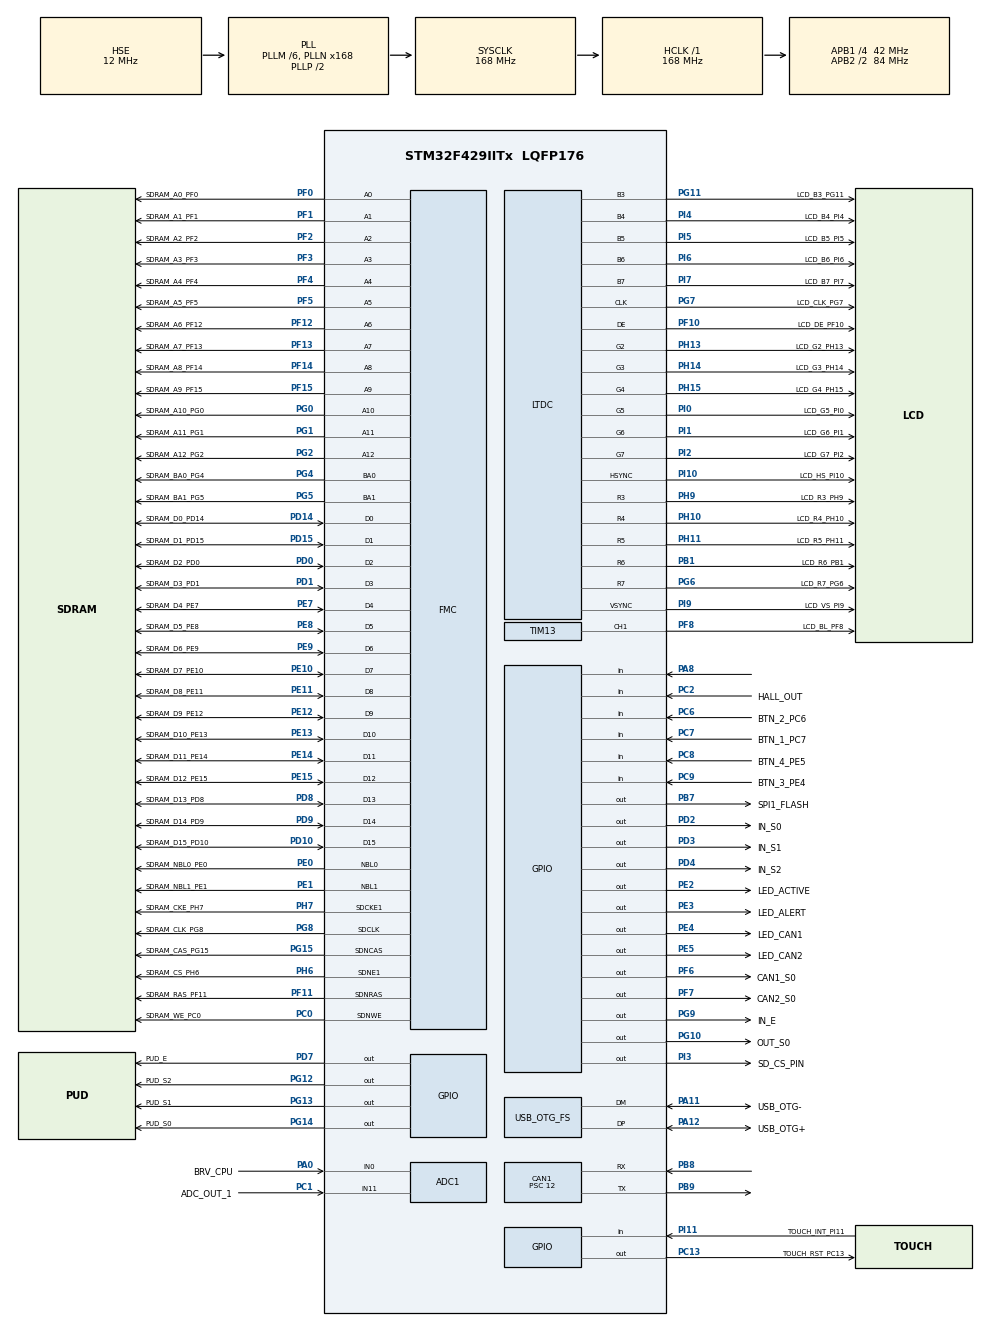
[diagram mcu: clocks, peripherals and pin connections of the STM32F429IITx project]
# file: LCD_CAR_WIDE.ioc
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ADC1.Channel-0\#ChannelRegularConversion=ADC_CHANNEL_11
ADC1.NbrOfConversionFlag=1
ADC1.Rank-0\#ChannelRegularConversion=1
ADC1.SamplingTime-0\#ChannelRegularConversion=ADC_SAMPLETIME_3CYCLES
ADC1.master=1
CAN1.BS1=CAN_BS1_4TQ
CAN1.BS2=CAN_BS2_2TQ
CAN1.CalculateBaudRate=500000
CAN1.CalculateTimeBit=2000
CAN1.CalculateTimeQuantum=285.7142857142857
CAN1.Prescaler=12
DMA2D.ColorMode=DMA2D_OUTPUT_RGB565
DMA2D.InputColorModeBackground=DMA2D_INPUT_RGB565
DMA2D.InputColorModeForeground=DMA2D_INPUT_RGB565
DMA2D.Mode=DMA2D_M2M_BLEND
FMC.CASLatency1=FMC_SDRAM_CAS_LATENCY_3
FMC.ColumnBitsNumber1=FMC_SDRAM_COLUMN_BITS_NUM_9
FMC.ExitSelfRefreshDelay1=8
FMC.LoadToActiveDelay1=2
FMC.RCDDelay1=2
FMC.RPDelay1=2
FMC.ReadBurst1=FMC_SDRAM_RBURST_ENABLE
FMC.ReadPipeDelay1=FMC_SDRAM_RPIPE_DELAY_1
FMC.RowCycleDelay1=7
FMC.SDClockPeriod1=FMC_SDRAM_CLOCK_PERIOD_2
FMC.SelfRefreshTime1=6
FMC.WriteRecoveryTime1=5
FREERTOS.Tasks01=START_Task,24,128,Start_START_Task,Default,NULL,Dynamic,NULL,NULL;TouchGFXTask,40,2048,TouchGFX_Task,As weak,NULL,Dynamic,NULL,NULL;LED_Task,8,128,Start_LED_Task,Default,NULL,Dynamic,NULL,NULL;CAN_Task,8,128,Start_CAN_Task,Default,NULL,Dynamic,NULL,NULL;ALERT_Task,8,128,Start_ALERT_Task,Default,NULL,Dynamic,NULL,NULL;RGB_Task,8,512,Start_RGB_Task,Default,NULL,Dynamic,NULL,NULL
FREERTOS.configASSERT(\ x\ )=if ((x) \=\= 0) {taskDISABLE_INTERRUPTS(); for( ;; );} 
FREERTOS.configMINIMAL_STACK_SIZE=64
FREERTOS.configPRIO_BITS=4
FREERTOS.configTIMER_QUEUE_LENGTH=10
FREERTOS.configTOTAL_HEAP_SIZE=128360
FREERTOS.configUSE_NEWLIB_REENTRANT=1
LTDC.ActiveH=1280
LTDC.ActiveW=480
LTDC.Alpha_L0=255
LTDC.Alpha_L1=255
LTDC.BlendingFactor1_L0=LTDC_BLENDING_FACTOR1_PAxCA
LTDC.BlendingFactor1_L1=LTDC_BLENDING_FACTOR1_PAxCA
LTDC.BlendingFactor2_L0=LTDC_BLENDING_FACTOR2_PAxCA
LTDC.BlendingFactor2_L1=LTDC_BLENDING_FACTOR2_PAxCA
LTDC.Blue_L0=0
LTDC.DEPolarity=LTDC_DEPOLARITY_AL
LTDC.FBStartAdress_L0=0xD0000000
LTDC.FBStartAdress_L1=0xD012C000
LTDC.Green=0
LTDC.Green_L0=0
LTDC.HBP=2
LTDC.HFP=2
LTDC.HSPolarity=LTDC_HSPOLARITY_AL
LTDC.HSync=2
LTDC.ImageHeight_L0=1280
LTDC.ImageHeight_L1=1280
LTDC.ImageWidth_L0=480
LTDC.ImageWidth_L1=480
LTDC.Layers=0
LTDC.PCPolarity=LTDC_PCPOLARITY_IPC
LTDC.PixelFormat_L0=LTDC_PIXEL_FORMAT_RGB565
LTDC.Red=0
LTDC.VBP=40
LTDC.VFP=10
LTDC.VSPolarity=LTDC_VSPOLARITY_AL
LTDC.VSync=20
LTDC.WindowX0_L0=0
LTDC.WindowX1_L0=480
LTDC.WindowX1_L1=480
LTDC.WindowY0_L0=0
LTDC.WindowY1_L0=1280
LTDC.WindowY1_L1=1280
Mcu.Family=STM32F4
Mcu.Name=STM32F429IITx
Mcu.Package=LQFP176
NVIC.CAN1_RX0_IRQn=true\:5\:0\:false\:false\:true\:true\:true\:true\:true
NVIC.DMA2D_IRQn=true\:5\:0\:false\:false\:true\:true\:true\:true\:true
NVIC.FMC_IRQn=true\:5\:0\:false\:false\:true\:true\:true\:true\:true
NVIC.LTDC_IRQn=true\:5\:0\:false\:false\:true\:true\:true\:true\:true
NVIC.OTG_FS_IRQn=true\:5\:0\:false\:false\:true\:true\:false\:true\:true
NVIC.PriorityGroup=NVIC_PRIORITYGROUP_4
NVIC.TIM6_DAC_IRQn=true\:15\:0\:false\:false\:true\:false\:false\:true\:true
NVIC.TimeBase=TIM6_DAC_IRQn
NVIC.TimeBaseIP=TIM6
PA0/WKUP.GPIO_Label=BRV_CPU
PA0/WKUP.Signal=ADCx_IN0
PA11.GPIO_Label=USB_OTG-
PA11.Mode=Device_Only
PA11.Signal=USB_OTG_FS_DM
PA12.GPIO_Label=USB_OTG+
PA12.Mode=Device_Only
PA12.Signal=USB_OTG_FS_DP
PA13.GPIO_Label=SWDIO
PA13.Mode=Serial_Wire
PA13.Signal=SYS_JTMS-SWDIO
PA14.GPIO_Label=SWCLK
PA14.Mode=Serial_Wire
PA14.Signal=SYS_JTCK-SWCLK
PA8.Signal=GPIO_Input
PB1.GPIO_Label=LCD_R6_PB1
PB1.GPIO_Mode=GPIO_MODE_AF_PP
PB1.GPIO_PuPd=GPIO_PULLUP
PB1.GPIO_Speed=GPIO_SPEED_FREQ_VERY_HIGH
PB1.Mode=RGB565
PB1.Signal=LTDC_R6
PB10.GPIO_Label=ESP_TX
PB10.Signal=USART3_TX
PB11.GPIO_Label=ESP_RX
PB11.Signal=USART3_RX
PB12.Signal=CAN2_RX
PB13.Signal=CAN2_TX
PB3.Signal=SPI1_SCK
PB4.Signal=SPI1_MISO
PB5.Signal=SPI1_MOSI
PB7.GPIO_Label=SPI1_FLASH
PB7.Signal=GPIO_Output
PB8.Mode=CAN_Activate
PB8.Signal=CAN1_RX
PB9.Mode=CAN_Activate
PB9.Signal=CAN1_TX
PC0.GPIO_Label=SDRAM_WE_PC0
PC0.Signal=FMC_SDNWE
PC1.GPIO_Label=ADC_OUT_1
PC1.Signal=ADCx_IN11
PC10.Signal=SPI3_SCK
PC11.Signal=SPI3_MISO
PC12.Signal=SPI3_MOSI
PC13.GPIO_Label=TOUCH_RST_PC13
PC13.Signal=GPIO_Output
PC2.GPIO_Label=HALL_OUT
PC2.Signal=GPIO_Input
PC6.GPIO_Label=BTN_2_PC6
PC6.Signal=GPIO_Input
PC7.GPIO_Label=BTN_1_PC7
PC7.Signal=GPIO_Input
PC8.GPIO_Label=BTN_4_PE5
PC8.Signal=GPIO_Input
PC9.GPIO_Label=BTN_3_PE4
PC9.Signal=GPIO_Input
PD0.GPIO_Label=SDRAM_D2_PD0
PD0.Signal=FMC_D2_DA2
PD1.GPIO_Label=SDRAM_D3_PD1
PD1.Signal=FMC_D3_DA3
PD10.GPIO_Label=SDRAM_D15_PD10
PD10.Signal=FMC_D15_DA15
PD14.GPIO_Label=SDRAM_D0_PD14
PD14.Signal=FMC_D0_DA0
PD15.GPIO_Label=SDRAM_D1_PD15
PD15.Signal=FMC_D1_DA1
PD2.GPIO_Label=IN_S0
PD2.Signal=GPIO_Output
PD3.GPIO_Label=IN_S1
PD3.Signal=GPIO_Output
PD4.GPIO_Label=IN_S2
PD4.Signal=GPIO_Output
PD6.GPIO_Label=LCD_B2_PD6
PD6.Signal=LTDC_B2
PD7.GPIO_Label=PUD_E
PD7.Signal=GPIO_Output
PD8.GPIO_Label=SDRAM_D13_PD8
PD8.Signal=FMC_D13_DA13
PD9.GPIO_Label=SDRAM_D14_PD9
PD9.Signal=FMC_D14_DA14
PE0.GPIO_Label=SDRAM_NBL0_PE0
PE0.Signal=FMC_NBL0
PE1.GPIO_Label=SDRAM_NBL1_PE1
PE1.Signal=FMC_NBL1
PE10.GPIO_Label=SDRAM_D7_PE10
PE10.Signal=FMC_D7_DA7
PE11.GPIO_Label=SDRAM_D8_PE11
PE11.Signal=FMC_D8_DA8
PE12.GPIO_Label=SDRAM_D9_PE12
PE12.Signal=FMC_D9_DA9
PE13.GPIO_Label=SDRAM_D10_PE13
PE13.Signal=FMC_D10_DA10
PE14.GPIO_Label=SDRAM_D11_PE14
PE14.Signal=FMC_D11_DA11
PE15.GPIO_Label=SDRAM_D12_PE15
PE15.Signal=FMC_D12_DA12
PE2.GPIO_Label=LED_ACTIVE
PE2.Signal=GPIO_Output
PE3.GPIO_Label=LED_ALERT
PE3.Signal=GPIO_Output
PE4.GPIO_Label=LED_CAN1
PE4.Signal=GPIO_Output
PE5.GPIO_Label=LED_CAN2
PE5.Signal=GPIO_Output
PE7.GPIO_Label=SDRAM_D4_PE7
PE7.Signal=FMC_D4_DA4
PE8.GPIO_Label=SDRAM_D5_PE8
PE8.Signal=FMC_D5_DA5
PE9.GPIO_Label=SDRAM_D6_PE9
PE9.Signal=FMC_D6_DA6
PF0.GPIO_Label=SDRAM_A0_PF0
PF0.Signal=FMC_A0
PF1.GPIO_Label=SDRAM_A1_PF1
PF1.Signal=FMC_A1
PF10.GPIO_Label=LCD_DE_PF10
PF10.GPIO_Mode=GPIO_MODE_AF_PP
PF10.GPIO_PuPd=GPIO_PULLUP
PF10.GPIO_Speed=GPIO_SPEED_FREQ_VERY_HIGH
PF10.Mode=RGB565
PF10.Signal=LTDC_DE
PF11.GPIO_Label=SDRAM_RAS_PF11
PF11.Signal=FMC_SDNRAS
PF12.GPIO_Label=SDRAM_A6_PF12
PF12.Signal=FMC_A6
PF13.GPIO_Label=SDRAM_A7_PF13
PF13.Signal=FMC_A7
PF14.GPIO_Label=SDRAM_A8_PF14
PF14.Signal=FMC_A8
PF15.GPIO_Label=SDRAM_A9_PF15
PF15.Signal=FMC_A9
PF2.GPIO_Label=SDRAM_A2_PF2
PF2.Signal=FMC_A2
PF3.GPIO_Label=SDRAM_A3_PF3
PF3.Signal=FMC_A3
PF4.GPIO_Label=SDRAM_A4_PF4
PF4.Signal=FMC_A4
PF5.GPIO_Label=SDRAM_A5_PF5
PF5.Signal=FMC_A5
PF6.GPIO_Label=CAN1_S0
PF6.GPIO_ModeDefaultOutputPP=GPIO_MODE_OUTPUT_PP
PF6.GPIO_PuPd=GPIO_PULLUP
PF6.PinState=GPIO_PIN_RESET
PF6.Signal=GPIO_Output
PF7.GPIO_Label=CAN2_S0
PF7.GPIO_ModeDefaultOutputPP=GPIO_MODE_OUTPUT_PP
PF7.GPIO_PuPd=GPIO_PULLUP
PF7.PinState=GPIO_PIN_RESET
PF7.Signal=GPIO_Output
PF8.GPIO_Label=LCD_BL_PF8
PF8.Signal=S_TIM13_CH1
PG0.GPIO_Label=SDRAM_A10_PG0
PG0.Signal=FMC_A10
PG1.GPIO_Label=SDRAM_A11_PG1
PG1.Signal=FMC_A11
PG10.GPIO_Label=OUT_S0
PG10.Signal=GPIO_Output
PG11.GPIO_Label=LCD_B3_PG11
PG11.GPIO_Mode=GPIO_MODE_AF_PP
PG11.GPIO_PuPd=GPIO_PULLUP
PG11.GPIO_Speed=GPIO_SPEED_FREQ_VERY_HIGH
PG11.Mode=RGB565
PG11.Signal=LTDC_B3
PG12.GPIO_Label=PUD_S2
PG12.Signal=GPIO_Output
PG13.GPIO_Label=PUD_S1
PG13.Signal=GPIO_Output
PG14.GPIO_Label=PUD_S0
PG14.Signal=GPIO_Output
PG15.GPIO_Label=SDRAM_CAS_PG15
PG15.Signal=FMC_SDNCAS
PG2.GPIO_Label=SDRAM_A12_PG2
PG2.Signal=FMC_A12
PG4.GPIO_Label=SDRAM_BA0_PG4
PG4.Signal=FMC_A14_BA0
PG5.GPIO_Label=SDRAM_BA1_PG5
PG5.Signal=FMC_A15_BA1
PG6.GPIO_Label=LCD_R7_PG6
PG6.GPIO_Mode=GPIO_MODE_AF_PP
PG6.GPIO_PuPd=GPIO_PULLUP
PG6.GPIO_Speed=GPIO_SPEED_FREQ_VERY_HIGH
PG6.Mode=RGB565
PG6.Signal=LTDC_R7
PG7.GPIO_Label=LCD_CLK_PG7
PG7.GPIO_Mode=GPIO_MODE_AF_PP
PG7.GPIO_PuPd=GPIO_PULLUP
PG7.GPIO_Speed=GPIO_SPEED_FREQ_VERY_HIGH
PG7.Mode=RGB565
PG7.Signal=LTDC_CLK
PG8.GPIO_Label=SDRAM_CLK_PG8
PG8.Signal=FMC_SDCLK
PG9.GPIO_Label=IN_E
PG9.Signal=GPIO_Output
PH0/OSC_IN.GPIO_Label=OSC_IN
PH0/OSC_IN.Mode=HSE-External-Oscillator
PH0/OSC_IN.Signal=RCC_OSC_IN
PH1/OSC_OUT.GPIO_Label=OSC_OUT
PH1/OSC_OUT.Mode=HSE-External-Oscillator
PH1/OSC_OUT.Signal=RCC_OSC_OUT
PH10.GPIO_Label=LCD_R4_PH10
PH10.GPIO_Mode=GPIO_MODE_AF_PP
PH10.GPIO_PuPd=GPIO_PULLUP
PH10.GPIO_Speed=GPIO_SPEED_FREQ_VERY_HIGH
PH10.Mode=RGB565
PH10.Signal=LTDC_R4
PH11.GPIO_Label=LCD_R5_PH11
PH11.GPIO_Mode=GPIO_MODE_AF_PP
PH11.GPIO_PuPd=GPIO_PULLUP
PH11.GPIO_Speed=GPIO_SPEED_FREQ_VERY_HIGH
PH11.Mode=RGB565
PH11.Signal=LTDC_R5
PH13.GPIO_Label=LCD_G2_PH13
PH13.GPIO_Mode=GPIO_MODE_AF_PP
PH13.GPIO_PuPd=GPIO_PULLUP
PH13.GPIO_Speed=GPIO_SPEED_FREQ_VERY_HIGH
PH13.Mode=RGB565
PH13.Signal=LTDC_G2
PH14.GPIO_Label=LCD_G3_PH14
PH14.GPIO_Mode=GPIO_MODE_AF_PP
PH14.GPIO_PuPd=GPIO_PULLUP
PH14.GPIO_Speed=GPIO_SPEED_FREQ_VERY_HIGH
PH14.Mode=RGB565
PH14.Signal=LTDC_G3
PH15.GPIO_Label=LCD_G4_PH15
PH15.GPIO_Mode=GPIO_MODE_AF_PP
PH15.GPIO_PuPd=GPIO_PULLUP
PH15.GPIO_Speed=GPIO_SPEED_FREQ_VERY_HIGH
PH15.Mode=RGB565
PH15.Signal=LTDC_G4
PH4.GPIO_Label=I2C2_SCL_PH4
PH4.Signal=I2C2_SCL
PH5.GPIO_Label=I2C2_SDA_PH5
PH5.Signal=I2C2_SDA
PH6.GPIO_Label=SDRAM_CS_PH6
PH6.Mode=SdramChipSelect2_1
PH6.Signal=FMC_SDNE1
PH7.GPIO_Label=SDRAM_CKE_PH7
PH7.Mode=SdramChipSelect2_1
PH7.Signal=FMC_SDCKE1
PH8.GPIO_Label=LCD_R2_PH8
PH8.Signal=LTDC_R2
PH9.GPIO_Label=LCD_R3_PH9
PH9.GPIO_Mode=GPIO_MODE_AF_PP
PH9.GPIO_PuPd=GPIO_PULLUP
PH9.GPIO_Speed=GPIO_SPEED_FREQ_VERY_HIGH
PH9.Mode=RGB565
PH9.Signal=LTDC_R3
PI0.GPIO_Label=LCD_G5_PI0
PI0.GPIO_Mode=GPIO_MODE_AF_PP
PI0.GPIO_PuPd=GPIO_PULLUP
PI0.GPIO_Speed=GPIO_SPEED_FREQ_VERY_HIGH
PI0.Mode=RGB565
PI0.Signal=LTDC_G5
PI1.GPIO_Label=LCD_G6_PI1
PI1.GPIO_Mode=GPIO_MODE_AF_PP
PI1.GPIO_PuPd=GPIO_PULLUP
PI1.GPIO_Speed=GPIO_SPEED_FREQ_VERY_HIGH
PI1.Mode=RGB565
PI1.Signal=LTDC_G6
PI10.GPIO_Label=LCD_HS_PI10
PI10.GPIO_Mode=GPIO_MODE_AF_PP
PI10.GPIO_PuPd=GPIO_PULLUP
PI10.GPIO_Speed=GPIO_SPEED_FREQ_VERY_HIGH
PI10.Mode=RGB565
PI10.Signal=LTDC_HSYNC
PI11.GPIO_Label=TOUCH_INT_PI11
PI11.Signal=GPIO_Input
PI2.GPIO_Label=LCD_G7_PI2
PI2.GPIO_Mode=GPIO_MODE_AF_PP
PI2.GPIO_PuPd=GPIO_PULLUP
PI2.GPIO_Speed=GPIO_SPEED_FREQ_VERY_HIGH
PI2.Mode=RGB565
PI2.Signal=LTDC_G7
PI3.GPIO_Label=SD_CS_PIN
PI3.Signal=GPIO_Output
PI4.GPIO_Label=LCD_B4_PI4
PI4.GPIO_Mode=GPIO_MODE_AF_PP
PI4.GPIO_PuPd=GPIO_PULLUP
PI4.GPIO_Speed=GPIO_SPEED_FREQ_VERY_HIGH
PI4.Mode=RGB565
PI4.Signal=LTDC_B4
PI5.GPIO_Label=LCD_B5_PI5
PI5.GPIO_Mode=GPIO_MODE_AF_PP
PI5.GPIO_PuPd=GPIO_PULLUP
PI5.GPIO_Speed=GPIO_SPEED_FREQ_VERY_HIGH
PI5.Mode=RGB565
PI5.Signal=LTDC_B5
PI6.GPIO_Label=LCD_B6_PI6
PI6.GPIO_Mode=GPIO_MODE_AF_PP
PI6.GPIO_PuPd=GPIO_PULLUP
PI6.GPIO_Speed=GPIO_SPEED_FREQ_VERY_HIGH
PI6.Mode=RGB565
PI6.Signal=LTDC_B6
PI7.GPIO_Label=LCD_B7_PI7
PI7.GPIO_Mode=GPIO_MODE_AF_PP
PI7.GPIO_PuPd=GPIO_PULLUP
PI7.GPIO_Speed=GPIO_SPEED_FREQ_VERY_HIGH
PI7.Mode=RGB565
PI7.Signal=LTDC_B7
PI9.GPIO_Label=LCD_VS_PI9
PI9.GPIO_Mode=GPIO_MODE_AF_PP
PI9.GPIO_PuPd=GPIO_PULLUP
PI9.GPIO_Speed=GPIO_SPEED_FREQ_VERY_HIGH
PI9.Mode=RGB565
PI9.Signal=LTDC_VSYNC
ProjectManager.HeapSize=0x400
ProjectManager.StackSize=0x800
ProjectManager.TargetToolchain=STM32CubeIDE
RCC.48MHZClocksFreq_Value=48000000
RCC.AHBFreq_Value=168000000
RCC.APB1CLKDivider=RCC_HCLK_DIV4
RCC.APB1Freq_Value=42000000
RCC.APB1TimFreq_Value=84000000
RCC.APB2CLKDivider=RCC_HCLK_DIV2
RCC.APB2Freq_Value=84000000
RCC.APB2TimFreq_Value=168000000
RCC.CortexFreq_Value=168000000
RCC.EXTERNAL_CLOCK_VALUE=12288000
RCC.EnbaleCSS=true
RCC.FLatency-AdvancedSettings=FLASH_LATENCY_5
RCC.HCLKFreq_Value=168000000
RCC.HSEUsed=1
RCC.HSE_VALUE=12000000
RCC.HSI_VALUE=16000000
RCC.I2SClockSource=I2S_CLOCK_PLL
RCC.LSEUsed=0
RCC.LSE_VALUE=32768
RCC.LSIUsed=0
RCC.PLLM=6
RCC.PLLN=168
RCC.PLLQ=7
RCC.PLLSAIN=50
RCC.PLLUsed=1
RCC.SAIClockSource_BlockA=SAI_CLKSOURCE_PLLSAI
RCC.SAIClockSource_BlockB=SAI_CLKSOURCE_PLLSAI
RCC.SYSCLKFreq_VALUE=168000000
RCC.SYSCLKSource=RCC_SYSCLKSOURCE_PLLCLK
RCC.VCOOutputFreq_Value=336000000
SH.ADCx_IN0.0=ADC1_IN0,IN0
SH.ADCx_IN11.0=ADC1_IN11,IN11
SH.FMC_A0.0=FMC_A0,13b-sda1
SH.FMC_A1.0=FMC_A1,13b-sda1
SH.FMC_A10.0=FMC_A10,13b-sda1
SH.FMC_A11.0=FMC_A11,13b-sda1
SH.FMC_A12.0=FMC_A12,13b-sda1
SH.FMC_A14_BA0.0=FMC_BA0,FourSdramBanks1
SH.FMC_A15_BA1.0=FMC_BA1,FourSdramBanks1
SH.FMC_A2.0=FMC_A2,13b-sda1
SH.FMC_A3.0=FMC_A3,13b-sda1
SH.FMC_A4.0=FMC_A4,13b-sda1
SH.FMC_A5.0=FMC_A5,13b-sda1
SH.FMC_A6.0=FMC_A6,13b-sda1
SH.FMC_A7.0=FMC_A7,13b-sda1
SH.FMC_A8.0=FMC_A8,13b-sda1
SH.FMC_A9.0=FMC_A9,13b-sda1
SH.FMC_D0_DA0.0=FMC_D0,sd-16b-d1
SH.FMC_D10_DA10.0=FMC_D10,sd-16b-d1
SH.FMC_D11_DA11.0=FMC_D11,sd-16b-d1
SH.FMC_D12_DA12.0=FMC_D12,sd-16b-d1
SH.FMC_D13_DA13.0=FMC_D13,sd-16b-d1
SH.FMC_D14_DA14.0=FMC_D14,sd-16b-d1
SH.FMC_D15_DA15.0=FMC_D15,sd-16b-d1
SH.FMC_D1_DA1.0=FMC_D1,sd-16b-d1
SH.FMC_D2_DA2.0=FMC_D2,sd-16b-d1
SH.FMC_D3_DA3.0=FMC_D3,sd-16b-d1
SH.FMC_D4_DA4.0=FMC_D4,sd-16b-d1
SH.FMC_D5_DA5.0=FMC_D5,sd-16b-d1
SH.FMC_D6_DA6.0=FMC_D6,sd-16b-d1
SH.FMC_D7_DA7.0=FMC_D7,sd-16b-d1
SH.FMC_D8_DA8.0=FMC_D8,sd-16b-d1
SH.FMC_D9_DA9.0=FMC_D9,sd-16b-d1
SH.FMC_NBL0.0=FMC_NBL0,Sd2ByteEnable1
SH.FMC_NBL1.0=FMC_NBL1,Sd2ByteEnable1
SH.FMC_SDCLK.0=FMC_SDCLK,13b-sda1
SH.FMC_SDNCAS.0=FMC_SDNCAS,13b-sda1
SH.FMC_SDNRAS.0=FMC_SDNRAS,13b-sda1
SH.FMC_SDNWE.0=FMC_SDNWE,13b-sda1
SH.S_TIM13_CH1.0=TIM13_CH1,PWM Generation1 CH1
STMicroelectronics.X-CUBE-TOUCHGFX.4.21.1.ApplicationCcGraphicsJjApplication=TouchGFXOoGenerator
STMicroelectronics.X-CUBE-TOUCHGFX.4.21.1.tgfx_address1=0xD0000000
STMicroelectronics.X-CUBE-TOUCHGFX.4.21.1.tgfx_address2=0xD012C000
STMicroelectronics.X-CUBE-TOUCHGFX.4.21.1.tgfx_buffering_strategy=Double
STMicroelectronics.X-CUBE-TOUCHGFX.4.21.1.tgfx_display_interface=disp_ltdc
STMicroelectronics.X-CUBE-TOUCHGFX.4.21.1.tgfx_hardware_accelerator=dma_2d
STMicroelectronics.X-CUBE-TOUCHGFX.4.21.1.tgfx_location=By Address
STMicroelectronics.X-CUBE-TOUCHGFX.4.21.1.tgfx_vsync=vsync_ltdc
STMicroelectronics.X-CUBE-TOUCHGFX.4.21.1_IsPackSelfContextualization=true
TIM1.AutoReloadPreload=TIM_AUTORELOAD_PRELOAD_DISABLE
TIM1.Period=210
TIM13.AutoReloadPreload=TIM_AUTORELOAD_PRELOAD_ENABLE
TIM13.Channel=TIM_CHANNEL_1
TIM13.Period=1000-1
TIM13.Prescaler=90-1
USB_DEVICE.CLASS_NAME_FS=CDC
USB_DEVICE.PID_CDC_FS=57701
USB_DEVICE.PRODUCT_STRING_CDC_FS=OPF Dash
USB_DEVICE.VirtualMode-CDC_FS=Cdc
USB_DEVICE.VirtualModeFS=Cdc_FS
USB_OTG_FS.VirtualMode=Device_Only
VP_CRC_VS_CRC.Mode=CRC_Activate
VP_DMA2D_VS_DMA2D.Mode=DMA2D_Activate
VP_FREERTOS_VS_CMSIS_V2.Mode=CMSIS_V2
VP_STMicroelectronics.X-CUBE-TOUCHGFX_VS_GraphicsJjApplication_4.21.1.Mode=GraphicsJjApplication
VP_SYS_VS_tim6.Mode=TIM6
VP_TIM13_VS_ClockSourceINT.Mode=Enable_Timer
VP_TIM1_VS_ClockSourceINT.Mode=Internal
VP_USB_DEVICE_VS_USB_DEVICE_CDC_FS.Mode=CDC_FS
board=custom

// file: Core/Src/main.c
/* USER CODE BEGIN Header */
/**
 ******************************************************************************
 * @file           : main.c
 * @brief          : Main program body
 ******************************************************************************
 * @attention
 *
 * <h2><center>&copy; Copyright (c) 2021 STMicroelectronics.
 * All rights reserved.</center></h2>
 *
 * This software component is licensed by ST under BSD 3-Clause license,
 * the "License"; You may not use this file except in compliance with the
 * License. You may obtain a copy of the License at:
 *                        opensource.org/licenses/BSD-3-Clause
 *
 ******************************************************************************
 */
/* USER CODE END Header */
#include "main.h"
#include "cmsis_os.h"
#include "app_touchgfx.h"
#include "usb_device.h"

/* USER CODE BEGIN Includes */
//#include <File_Handling.h>
#include <stdio.h>
#include "Globals.h"
#include "extern.h"
#include "sdram.h"
#include "WS2812/WS2812.hpp"

//Setup
#include "Setup/Dash/setupDash.h"
#include "Setup/Field/setupField.h"

/* USER CODE END Includes */

/* USER CODE BEGIN PM */
//#define LCD_ORIENTATION_LANDSCAPE 0x01

/* USER CODE END PM */

ADC_HandleTypeDef hadc1;

CAN_HandleTypeDef hcan1;

CRC_HandleTypeDef hcrc;

DMA2D_HandleTypeDef hdma2d;

LTDC_HandleTypeDef hltdc;

TIM_HandleTypeDef htim1;
TIM_HandleTypeDef htim13;

SDRAM_HandleTypeDef hsdram1;

/* Definitions for START_Task */
osThreadId_t START_TaskHandle;
const osThreadAttr_t START_Task_attributes = {
  .name = "START_Task",
  .stack_size = 128 * 4,
  .priority = (osPriority_t) osPriorityNormal,
};
/* Definitions for TouchGFXTask */
osThreadId_t TouchGFXTaskHandle;
const osThreadAttr_t TouchGFXTask_attributes = {
  .name = "TouchGFXTask",
  .stack_size = 2048 * 4,
  .priority = (osPriority_t) osPriorityHigh,
};
/* Definitions for LED_Task */
osThreadId_t LED_TaskHandle;
const osThreadAttr_t LED_Task_attributes = {
  .name = "LED_Task",
  .stack_size = 128 * 4,
  .priority = (osPriority_t) osPriorityLow,
};
/* Definitions for CAN_Task */
osThreadId_t CAN_TaskHandle;
const osThreadAttr_t CAN_Task_attributes = {
  .name = "CAN_Task",
  .stack_size = 128 * 4,
  .priority = (osPriority_t) osPriorityLow,
};
/* Definitions for ALERT_Task */
osThreadId_t ALERT_TaskHandle;
const osThreadAttr_t ALERT_Task_attributes = {
  .name = "ALERT_Task",
  .stack_size = 128 * 4,
  .priority = (osPriority_t) osPriorityLow,
};
/* Definitions for RGB_Task */
osThreadId_t RGB_TaskHandle;
const osThreadAttr_t RGB_Task_attributes = {
  .name = "RGB_Task",
  .stack_size = 512 * 4,
  .priority = (osPriority_t) osPriorityLow,
};
/* USER CODE BEGIN PV */
FMC_SDRAM_CommandTypeDef command;

Statuses Current_Status;

CAN_TxHeaderTypeDef TxHeader;
CAN_RxHeaderTypeDef RxHeader;
uint8_t TxData[8];
uint8_t RxData[8];

uint8_t uartTransmitBufferSize;
uint8_t uartTransmitBuffer[128];

/* USER CODE END PV */

void SystemClock_Config(void);
static void MX_GPIO_Init(void);
static void MX_LTDC_Init(void);
static void MX_DMA2D_Init(void);
static void MX_FMC_Init(void);
static void MX_CRC_Init(void);
static void MX_TIM13_Init(void);
static void MX_CAN1_Init(void);
static void MX_ADC1_Init(void);
static void MX_TIM1_Init(void);
void Start_START_Task(void *argument);
void TouchGFX_Task(void *argument);
void Start_LED_Task(void *argument);
void Start_CAN_Task(void *argument);
void Start_ALERT_Task(void *argument);
void Start_RGB_Task(void *argument);

int main(void)
{

  /* MCU Configuration--------------------------------------------------------*/

  /* Reset of all peripherals, Initializes the Flash interface and the Systick. */
  HAL_Init();

  /* Configure the system clock */
  SystemClock_Config();

  /* Initialize all configured peripherals */
  MX_GPIO_Init();
  MX_LTDC_Init();
  MX_DMA2D_Init();
  MX_FMC_Init();
  MX_CRC_Init();
  MX_TIM13_Init();
  MX_CAN1_Init();
  MX_ADC1_Init();
  MX_TIM1_Init();
  MX_TouchGFX_Init();
  /* Call PreOsInit function */
  MX_TouchGFX_PreOSInit();
  /* USER CODE BEGIN 2 */

  HAL_TIM_PWM_Start(&htim13, TIM_CHANNEL_1);
  initWS2812();

  /* USER CODE END 2 */

  /* Init scheduler */
  osKernelInitialize();

  /* Create the thread(s) */
  /* creation of START_Task */
  START_TaskHandle = osThreadNew(Start_START_Task, NULL, &START_Task_attributes);

  /* creation of TouchGFXTask */
  TouchGFXTaskHandle = osThreadNew(TouchGFX_Task, NULL, &TouchGFXTask_attributes);

  /* creation of LED_Task */
  LED_TaskHandle = osThreadNew(Start_LED_Task, NULL, &LED_Task_attributes);

  /* creation of CAN_Task */
  CAN_TaskHandle = osThreadNew(Start_CAN_Task, NULL, &CAN_Task_attributes);

  /* creation of ALERT_Task */
  ALERT_TaskHandle = osThreadNew(Start_ALERT_Task, NULL, &ALERT_Task_attributes);

  /* creation of RGB_Task */
  RGB_TaskHandle = osThreadNew(Start_RGB_Task, NULL, &RGB_Task_attributes);

  /* Start scheduler */
  osKernelStart();

  /* We should never get here as control is now taken by the scheduler */
  /* Infinite loop */
	while (1) {

	}
}

void SystemClock_Config(void)
{
  RCC_OscInitTypeDef RCC_OscInitStruct = {0};
  RCC_ClkInitTypeDef RCC_ClkInitStruct = {0};

  /** Configure the main internal regulator output voltage
  */
  __HAL_RCC_PWR_CLK_ENABLE();
  __HAL_PWR_VOLTAGESCALING_CONFIG(PWR_REGULATOR_VOLTAGE_SCALE1);

  /** Initializes the RCC Oscillators according to the specified parameters
  * in the RCC_OscInitTypeDef structure.
  */
  RCC_OscInitStruct.OscillatorType = RCC_OSCILLATORTYPE_HSE;
  RCC_OscInitStruct.HSEState = RCC_HSE_ON;
  RCC_OscInitStruct.PLL.PLLState = RCC_PLL_ON;
  RCC_OscInitStruct.PLL.PLLSource = RCC_PLLSOURCE_HSE;
  RCC_OscInitStruct.PLL.PLLM = 6;
  RCC_OscInitStruct.PLL.PLLN = 168;
  RCC_OscInitStruct.PLL.PLLP = RCC_PLLP_DIV2;
  RCC_OscInitStruct.PLL.PLLQ = 7;
  if (HAL_RCC_OscConfig(&RCC_OscInitStruct) != HAL_OK)
  {
    Error_Handler();
  }

  /** Initializes the CPU, AHB and APB buses clocks
  */
  RCC_ClkInitStruct.ClockType = RCC_CLOCKTYPE_HCLK|RCC_CLOCKTYPE_SYSCLK
                              |RCC_CLOCKTYPE_PCLK1|RCC_CLOCKTYPE_PCLK2;
  RCC_ClkInitStruct.SYSCLKSource = RCC_SYSCLKSOURCE_PLLCLK;
  RCC_ClkInitStruct.AHBCLKDivider = RCC_SYSCLK_DIV1;
  RCC_ClkInitStruct.APB1CLKDivider = RCC_HCLK_DIV4;
  RCC_ClkInitStruct.APB2CLKDivider = RCC_HCLK_DIV2;

  if (HAL_RCC_ClockConfig(&RCC_ClkInitStruct, FLASH_LATENCY_5) != HAL_OK)
  {
    Error_Handler();
  }

  /** Enables the Clock Security System
  */
  HAL_RCC_EnableCSS();
}

static void MX_ADC1_Init(void)
{

  ADC_ChannelConfTypeDef sConfig = {0};

  /** Configure the global features of the ADC (Clock, Resolution, Data Alignment and number of conversion)
  */
  hadc1.Instance = ADC1;
  hadc1.Init.ClockPrescaler = ADC_CLOCK_SYNC_PCLK_DIV4;
  hadc1.Init.Resolution = ADC_RESOLUTION_12B;
  hadc1.Init.ScanConvMode = DISABLE;
  hadc1.Init.ContinuousConvMode = DISABLE;
  hadc1.Init.DiscontinuousConvMode = DISABLE;
  hadc1.Init.ExternalTrigConvEdge = ADC_EXTERNALTRIGCONVEDGE_NONE;
  hadc1.Init.ExternalTrigConv = ADC_SOFTWARE_START;
  hadc1.Init.DataAlign = ADC_DATAALIGN_RIGHT;
  hadc1.Init.NbrOfConversion = 1;
  hadc1.Init.DMAContinuousRequests = DISABLE;
  hadc1.Init.EOCSelection = ADC_EOC_SINGLE_CONV;
  if (HAL_ADC_Init(&hadc1) != HAL_OK)
  {
    Error_Handler();
  }

  /** Configure for the selected ADC regular channel its corresponding rank in the sequencer and its sample time.
  */
  sConfig.Channel = ADC_CHANNEL_11;
  sConfig.Rank = 1;
  sConfig.SamplingTime = ADC_SAMPLETIME_3CYCLES;
  if (HAL_ADC_ConfigChannel(&hadc1, &sConfig) != HAL_OK)
  {
    Error_Handler();
  }

}

static void MX_CAN1_Init(void)
{

  /* USER CODE BEGIN CAN1_Init 0 */

	CAN_FilterTypeDef sFilterConfig; //declare CAN filter structure
  /* USER CODE END CAN1_Init 0 */

  hcan1.Instance = CAN1;
  hcan1.Init.Prescaler = 12;
  hcan1.Init.Mode = CAN_MODE_NORMAL;
  hcan1.Init.SyncJumpWidth = CAN_SJW_1TQ;
  hcan1.Init.TimeSeg1 = CAN_BS1_4TQ;
  hcan1.Init.TimeSeg2 = CAN_BS2_2TQ;
  hcan1.Init.TimeTriggeredMode = DISABLE;
  hcan1.Init.AutoBusOff = DISABLE;
  hcan1.Init.AutoWakeUp = DISABLE;
  hcan1.Init.AutoRetransmission = DISABLE;
  hcan1.Init.ReceiveFifoLocked = DISABLE;
  hcan1.Init.TransmitFifoPriority = DISABLE;
  if (HAL_CAN_Init(&hcan1) != HAL_OK)
  {
    Error_Handler();
  }
  /* USER CODE BEGIN CAN1_Init 2 */
	sFilterConfig.FilterBank = 15;
	sFilterConfig.FilterMode = CAN_FILTERMODE_IDMASK;
	sFilterConfig.FilterScale = CAN_FILTERSCALE_32BIT;
	sFilterConfig.FilterIdHigh = 0x0000;
	sFilterConfig.FilterIdLow = 0x0000;
	sFilterConfig.FilterMaskIdHigh = 0x0000;
	sFilterConfig.FilterMaskIdLow = 0x0000;
	sFilterConfig.FilterFIFOAssignment = CAN_RX_FIFO0;
	sFilterConfig.FilterActivation = ENABLE;
	//sFilterConfig.SlaveStartFilterBank = 14;
	if (HAL_CAN_ConfigFilter(&hcan1, &sFilterConfig) != HAL_OK) {
		/* Filter configuration Error */
		Error_Handler();
	}
	if (HAL_CAN_Start(&hcan1) != HAL_OK) {
		/* Start Error */
		Error_Handler();
	}

	__HAL_RCC_CAN1_CLK_ENABLE();
	//__HAL_RCC_CAN2_CLK_ENABLE();
  /* USER CODE END CAN1_Init 2 */

}

static void MX_CRC_Init(void)
{

  hcrc.Instance = CRC;
  if (HAL_CRC_Init(&hcrc) != HAL_OK)
  {
    Error_Handler();
  }

}

static void MX_DMA2D_Init(void)
{

  hdma2d.Instance = DMA2D;
  hdma2d.Init.Mode = DMA2D_M2M_BLEND;
  hdma2d.Init.ColorMode = DMA2D_OUTPUT_RGB565;
  hdma2d.Init.OutputOffset = 0;
  hdma2d.LayerCfg[0].InputOffset = 0;
  hdma2d.LayerCfg[0].InputColorMode = DMA2D_INPUT_RGB565;
  hdma2d.LayerCfg[0].AlphaMode = DMA2D_NO_MODIF_ALPHA;
  hdma2d.LayerCfg[0].InputAlpha = 0;
  hdma2d.LayerCfg[1].InputOffset = 0;
  hdma2d.LayerCfg[1].InputColorMode = DMA2D_INPUT_RGB565;
  hdma2d.LayerCfg[1].AlphaMode = DMA2D_NO_MODIF_ALPHA;
  hdma2d.LayerCfg[1].InputAlpha = 0;
  if (HAL_DMA2D_Init(&hdma2d) != HAL_OK)
  {
    Error_Handler();
  }
  if (HAL_DMA2D_ConfigLayer(&hdma2d, 0) != HAL_OK)
  {
    Error_Handler();
  }
  if (HAL_DMA2D_ConfigLayer(&hdma2d, 1) != HAL_OK)
  {
    Error_Handler();
  }

}

static void MX_LTDC_Init(void)
{

  LTDC_LayerCfgTypeDef pLayerCfg = {0};

  hltdc.Instance = LTDC;
  hltdc.Init.HSPolarity = LTDC_HSPOLARITY_AL;
  hltdc.Init.VSPolarity = LTDC_VSPOLARITY_AL;
  hltdc.Init.DEPolarity = LTDC_DEPOLARITY_AL;
  hltdc.Init.PCPolarity = LTDC_PCPOLARITY_IPC;
  hltdc.Init.HorizontalSync = 1;
  hltdc.Init.VerticalSync = 19;
  hltdc.Init.AccumulatedHBP = 3;
  hltdc.Init.AccumulatedVBP = 59;
  hltdc.Init.AccumulatedActiveW = 483;
  hltdc.Init.AccumulatedActiveH = 1339;
  hltdc.Init.TotalWidth = 485;
  hltdc.Init.TotalHeigh = 1349;
  hltdc.Init.Backcolor.Blue = 0;
  hltdc.Init.Backcolor.Green = 0;
  hltdc.Init.Backcolor.Red = 0;
  if (HAL_LTDC_Init(&hltdc) != HAL_OK)
  {
    Error_Handler();
  }
  pLayerCfg.WindowX0 = 0;
  pLayerCfg.WindowX1 = 480;
  pLayerCfg.WindowY0 = 0;
  pLayerCfg.WindowY1 = 1280;
  pLayerCfg.PixelFormat = LTDC_PIXEL_FORMAT_RGB565;
  pLayerCfg.Alpha = 255;
  pLayerCfg.Alpha0 = 0;
  pLayerCfg.BlendingFactor1 = LTDC_BLENDING_FACTOR1_PAxCA;
  pLayerCfg.BlendingFactor2 = LTDC_BLENDING_FACTOR2_PAxCA;
  pLayerCfg.FBStartAdress = 0xD0000000;
  pLayerCfg.ImageWidth = 480;
  pLayerCfg.ImageHeight = 1280;
  pLayerCfg.Backcolor.Blue = 0;
  pLayerCfg.Backcolor.Green = 0;
  pLayerCfg.Backcolor.Red = 0;
  if (HAL_LTDC_ConfigLayer(&hltdc, &pLayerCfg, 0) != HAL_OK)
  {
    Error_Handler();
  }

}

static void MX_TIM1_Init(void)
{

  TIM_ClockConfigTypeDef sClockSourceConfig = {0};
  TIM_MasterConfigTypeDef sMasterConfig = {0};

  htim1.Instance = TIM1;
  htim1.Init.Prescaler = 0;
  htim1.Init.CounterMode = TIM_COUNTERMODE_UP;
  htim1.Init.Period = 210;
  htim1.Init.ClockDivision = TIM_CLOCKDIVISION_DIV1;
  htim1.Init.RepetitionCounter = 0;
  htim1.Init.AutoReloadPreload = TIM_AUTORELOAD_PRELOAD_DISABLE;
  if (HAL_TIM_Base_Init(&htim1) != HAL_OK)
  {
    Error_Handler();
  }
  sClockSourceConfig.ClockSource = TIM_CLOCKSOURCE_INTERNAL;
  if (HAL_TIM_ConfigClockSource(&htim1, &sClockSourceConfig) != HAL_OK)
  {
    Error_Handler();
  }
  sMasterConfig.MasterOutputTrigger = TIM_TRGO_RESET;
  sMasterConfig.MasterSlaveMode = TIM_MASTERSLAVEMODE_DISABLE;
  if (HAL_TIMEx_MasterConfigSynchronization(&htim1, &sMasterConfig) != HAL_OK)
  {
    Error_Handler();
  }

}

static void MX_TIM13_Init(void)
{

  TIM_OC_InitTypeDef sConfigOC = {0};

  htim13.Instance = TIM13;
  htim13.Init.Prescaler = 90-1;
  htim13.Init.CounterMode = TIM_COUNTERMODE_UP;
  htim13.Init.Period = 1000-1;
  htim13.Init.ClockDivision = TIM_CLOCKDIVISION_DIV1;
  htim13.Init.AutoReloadPreload = TIM_AUTORELOAD_PRELOAD_ENABLE;
  if (HAL_TIM_Base_Init(&htim13) != HAL_OK)
  {
    Error_Handler();
  }
  if (HAL_TIM_PWM_Init(&htim13) != HAL_OK)
  {
    Error_Handler();
  }
  sConfigOC.OCMode = TIM_OCMODE_PWM1;
  sConfigOC.Pulse = 0;
  sConfigOC.OCPolarity = TIM_OCPOLARITY_HIGH;
  sConfigOC.OCFastMode = TIM_OCFAST_DISABLE;
  if (HAL_TIM_PWM_ConfigChannel(&htim13, &sConfigOC, TIM_CHANNEL_1) != HAL_OK)
  {
    Error_Handler();
  }
  HAL_TIM_MspPostInit(&htim13);

}

/* FMC initialization function */
static void MX_FMC_Init(void)
{

  FMC_SDRAM_TimingTypeDef SdramTiming = {0};

  /** Perform the SDRAM1 memory initialization sequence
  */
  hsdram1.Instance = FMC_SDRAM_DEVICE;
  /* hsdram1.Init */
  hsdram1.Init.SDBank = FMC_SDRAM_BANK2;
  hsdram1.Init.ColumnBitsNumber = FMC_SDRAM_COLUMN_BITS_NUM_9;
  hsdram1.Init.RowBitsNumber = FMC_SDRAM_ROW_BITS_NUM_13;
  hsdram1.Init.MemoryDataWidth = FMC_SDRAM_MEM_BUS_WIDTH_16;
  hsdram1.Init.InternalBankNumber = FMC_SDRAM_INTERN_BANKS_NUM_4;
  hsdram1.Init.CASLatency = FMC_SDRAM_CAS_LATENCY_3;
  hsdram1.Init.WriteProtection = FMC_SDRAM_WRITE_PROTECTION_DISABLE;
  hsdram1.Init.SDClockPeriod = FMC_SDRAM_CLOCK_PERIOD_2;
  hsdram1.Init.ReadBurst = FMC_SDRAM_RBURST_ENABLE;
  hsdram1.Init.ReadPipeDelay = FMC_SDRAM_RPIPE_DELAY_1;
  /* SdramTiming */
  SdramTiming.LoadToActiveDelay = 2;
  SdramTiming.ExitSelfRefreshDelay = 8;
  SdramTiming.SelfRefreshTime = 6;
  SdramTiming.RowCycleDelay = 7;
  SdramTiming.WriteRecoveryTime = 5;
  SdramTiming.RPDelay = 2;
  SdramTiming.RCDDelay = 2;

  if (HAL_SDRAM_Init(&hsdram1, &SdramTiming) != HAL_OK)
  {
    Error_Handler( );
  }

  /* USER CODE BEGIN FMC_Init 2 */
	FMC_SDRAM_CommandTypeDef command;
	if (SDRAM_Initialization_Sequence(&hsdram1, &command) != HAL_OK) {
		Error_Handler();
	}
  /* USER CODE END FMC_Init 2 */
}

static void MX_GPIO_Init(void)
{
  GPIO_InitTypeDef GPIO_InitStruct = {0};

  /* GPIO Ports Clock Enable */
  __HAL_RCC_GPIOE_CLK_ENABLE();
  __HAL_RCC_GPIOC_CLK_ENABLE();
  __HAL_RCC_GPIOI_CLK_ENABLE();
  __HAL_RCC_GPIOF_CLK_ENABLE();
  __HAL_RCC_GPIOH_CLK_ENABLE();
  __HAL_RCC_GPIOA_CLK_ENABLE();
  __HAL_RCC_GPIOB_CLK_ENABLE();
  __HAL_RCC_GPIOG_CLK_ENABLE();
  __HAL_RCC_GPIOD_CLK_ENABLE();

  /*Configure GPIO pin Output Level */
  HAL_GPIO_WritePin(GPIOE, LED_ACTIVE_Pin|LED_ALERT_Pin|LED_CAN1_Pin|LED_CAN2_Pin, GPIO_PIN_RESET);

  /*Configure GPIO pin Output Level */
  HAL_GPIO_WritePin(TOUCH_RST_PC13_GPIO_Port, TOUCH_RST_PC13_Pin, GPIO_PIN_RESET);

  /*Configure GPIO pin Output Level */
  HAL_GPIO_WritePin(GPIOF, CAN1_S0_Pin|CAN2_S0_Pin, GPIO_PIN_RESET);

  /*Configure GPIO pin Output Level */
  HAL_GPIO_WritePin(SD_CS_PIN_GPIO_Port, SD_CS_PIN_Pin, GPIO_PIN_RESET);

  /*Configure GPIO pin Output Level */
  HAL_GPIO_WritePin(GPIOD, IN_S0_Pin|IN_S1_Pin|IN_S2_Pin|PUD_E_Pin, GPIO_PIN_RESET);

  /*Configure GPIO pin Output Level */
  HAL_GPIO_WritePin(GPIOG, IN_E_Pin|OUT_S0_Pin|PUD_S2_Pin|PUD_S1_Pin
                          |PUD_S0_Pin, GPIO_PIN_RESET);

  /*Configure GPIO pin Output Level */
  HAL_GPIO_WritePin(SPI1_FLASH_GPIO_Port, SPI1_FLASH_Pin, GPIO_PIN_RESET);

  /*Configure GPIO pins : LED_ACTIVE_Pin LED_ALERT_Pin LED_CAN1_Pin LED_CAN2_Pin */
  GPIO_InitStruct.Pin = LED_ACTIVE_Pin|LED_ALERT_Pin|LED_CAN1_Pin|LED_CAN2_Pin;
  GPIO_InitStruct.Mode = GPIO_MODE_OUTPUT_PP;
  GPIO_InitStruct.Pull = GPIO_NOPULL;
  GPIO_InitStruct.Speed = GPIO_SPEED_FREQ_LOW;
  HAL_GPIO_Init(GPIOE, &GPIO_InitStruct);

  /*Configure GPIO pin : TOUCH_RST_PC13_Pin */
  GPIO_InitStruct.Pin = TOUCH_RST_PC13_Pin;
  GPIO_InitStruct.Mode = GPIO_MODE_OUTPUT_PP;
  GPIO_InitStruct.Pull = GPIO_NOPULL;
  GPIO_InitStruct.Speed = GPIO_SPEED_FREQ_LOW;
  HAL_GPIO_Init(TOUCH_RST_PC13_GPIO_Port, &GPIO_InitStruct);

  /*Configure GPIO pin : TOUCH_INT_PI11_Pin */
  GPIO_InitStruct.Pin = TOUCH_INT_PI11_Pin;
  GPIO_InitStruct.Mode = GPIO_MODE_INPUT;
  GPIO_InitStruct.Pull = GPIO_NOPULL;
  HAL_GPIO_Init(TOUCH_INT_PI11_GPIO_Port, &GPIO_InitStruct);

  /*Configure GPIO pins : CAN1_S0_Pin CAN2_S0_Pin */
  GPIO_InitStruct.Pin = CAN1_S0_Pin|CAN2_S0_Pin;
  GPIO_InitStruct.Mode = GPIO_MODE_OUTPUT_PP;
  GPIO_InitStruct.Pull = GPIO_PULLUP;
  GPIO_InitStruct.Speed = GPIO_SPEED_FREQ_LOW;
  HAL_GPIO_Init(GPIOF, &GPIO_InitStruct);

  /*Configure GPIO pins : HALL_OUT_Pin BTN_2_PC6_Pin BTN_1_PC7_Pin BTN_4_PE5_Pin
                           BTN_3_PE4_Pin */
  GPIO_InitStruct.Pin = HALL_OUT_Pin|BTN_2_PC6_Pin|BTN_1_PC7_Pin|BTN_4_PE5_Pin
                          |BTN_3_PE4_Pin;
  GPIO_InitStruct.Mode = GPIO_MODE_INPUT;
  GPIO_InitStruct.Pull = GPIO_NOPULL;
  HAL_GPIO_Init(GPIOC, &GPIO_InitStruct);

  /*Configure GPIO pins : I2C2_SCL_PH4_Pin I2C2_SDA_PH5_Pin */
  GPIO_InitStruct.Pin = I2C2_SCL_PH4_Pin|I2C2_SDA_PH5_Pin;
  GPIO_InitStruct.Mode = GPIO_MODE_AF_OD;
  GPIO_InitStruct.Pull = GPIO_NOPULL;
  GPIO_InitStruct.Speed = GPIO_SPEED_FREQ_VERY_HIGH;
  GPIO_InitStruct.Alternate = GPIO_AF4_I2C2;
  HAL_GPIO_Init(GPIOH, &GPIO_InitStruct);

  /*Configure GPIO pins : ESP_TX_Pin ESP_RX_Pin */
  GPIO_InitStruct.Pin = ESP_TX_Pin|ESP_RX_Pin;
  GPIO_InitStruct.Mode = GPIO_MODE_AF_PP;
  GPIO_InitStruct.Pull = GPIO_NOPULL;
  GPIO_InitStruct.Speed = GPIO_SPEED_FREQ_VERY_HIGH;
  GPIO_InitStruct.Alternate = GPIO_AF7_USART3;
  HAL_GPIO_Init(GPIOB, &GPIO_InitStruct);

  /*Configure GPIO pins : PB12 PB13 */
  GPIO_InitStruct.Pin = GPIO_PIN_12|GPIO_PIN_13;
  GPIO_InitStruct.Mode = GPIO_MODE_AF_PP;
  GPIO_InitStruct.Pull = GPIO_NOPULL;
  GPIO_InitStruct.Speed = GPIO_SPEED_FREQ_VERY_HIGH;
  GPIO_InitStruct.Alternate = GPIO_AF9_CAN2;
  HAL_GPIO_Init(GPIOB, &GPIO_InitStruct);

  /*Configure GPIO pin : PA8 */
  GPIO_InitStruct.Pin = GPIO_PIN_8;
  GPIO_InitStruct.Mode = GPIO_MODE_INPUT;
  GPIO_InitStruct.Pull = GPIO_NOPULL;
  HAL_GPIO_Init(GPIOA, &GPIO_InitStruct);

  /*Configure GPIO pin : SD_CS_PIN_Pin */
  GPIO_InitStruct.Pin = SD_CS_PIN_Pin;
  GPIO_InitStruct.Mode = GPIO_MODE_OUTPUT_PP;
  GPIO_InitStruct.Pull = GPIO_NOPULL;
  GPIO_InitStruct.Speed = GPIO_SPEED_FREQ_LOW;
  HAL_GPIO_Init(SD_CS_PIN_GPIO_Port, &GPIO_InitStruct);

  /*Configure GPIO pins : PC10 PC11 PC12 */
  GPIO_InitStruct.Pin = GPIO_PIN_10|GPIO_PIN_11|GPIO_PIN_12;
  GPIO_InitStruct.Mode = GPIO_MODE_AF_PP;
  GPIO_InitStruct.Pull = GPIO_NOPULL;
  GPIO_InitStruct.Speed = GPIO_SPEED_FREQ_VERY_HIGH;
  GPIO_InitStruct.Alternate = GPIO_AF6_SPI3;
  HAL_GPIO_Init(GPIOC, &GPIO_InitStruct);

  /*Configure GPIO pins : IN_S0_Pin IN_S1_Pin IN_S2_Pin PUD_E_Pin */
  GPIO_InitStruct.Pin = IN_S0_Pin|IN_S1_Pin|IN_S2_Pin|PUD_E_Pin;
  GPIO_InitStruct.Mode = GPIO_MODE_OUTPUT_PP;
  GPIO_InitStruct.Pull = GPIO_NOPULL;
  GPIO_InitStruct.Speed = GPIO_SPEED_FREQ_LOW;
  HAL_GPIO_Init(GPIOD, &GPIO_InitStruct);

  /*Configure GPIO pins : IN_E_Pin OUT_S0_Pin PUD_S2_Pin PUD_S1_Pin
                           PUD_S0_Pin */
  GPIO_InitStruct.Pin = IN_E_Pin|OUT_S0_Pin|PUD_S2_Pin|PUD_S1_Pin
                          |PUD_S0_Pin;
  GPIO_InitStruct.Mode = GPIO_MODE_OUTPUT_PP;
  GPIO_InitStruct.Pull = GPIO_NOPULL;
  GPIO_InitStruct.Speed = GPIO_SPEED_FREQ_LOW;
  HAL_GPIO_Init(GPIOG, &GPIO_InitStruct);

  /*Configure GPIO pins : PB3 PB4 PB5 */
  GPIO_InitStruct.Pin = GPIO_PIN_3|GPIO_PIN_4|GPIO_PIN_5;
  GPIO_InitStruct.Mode = GPIO_MODE_AF_PP;
  GPIO_InitStruct.Pull = GPIO_NOPULL;
  GPIO_InitStruct.Speed = GPIO_SPEED_FREQ_VERY_HIGH;
  GPIO_InitStruct.Alternate = GPIO_AF5_SPI1;
  HAL_GPIO_Init(GPIOB, &GPIO_InitStruct);

  /*Configure GPIO pin : SPI1_FLASH_Pin */
  GPIO_InitStruct.Pin = SPI1_FLASH_Pin;
  GPIO_InitStruct.Mode = GPIO_MODE_OUTPUT_PP;
  GPIO_InitStruct.Pull = GPIO_NOPULL;
  GPIO_InitStruct.Speed = GPIO_SPEED_FREQ_LOW;
  HAL_GPIO_Init(SPI1_FLASH_GPIO_Port, &GPIO_InitStruct);

}

/* USER CODE BEGIN 4 */

float mapFloat(float x, float in_min, float in_max, float out_min,
		float out_max) {
	return (x - in_min) * (out_max - out_min) / (in_max - in_min) + out_min;
}

long mapInt(float x, float in_min, float in_max, int out_min, int out_max) {
	return (int) ((x - in_min) * (out_max - out_min) / (in_max - in_min)
			+ out_min);
}

/* USER CODE END 4 */

void Start_START_Task(void *argument)
{
  /* init code for USB_DEVICE */
  MX_USB_DEVICE_Init();
  /* USER CODE BEGIN 5 */
	//htim13.Instance->CCR1 = (htim13.Instance->ARR) * 0.99;
	Current_Status.LED_BRIGHTNESS = LED_DEFAULT_BRIGHTNESS;
	Current_Status.LCD_BRIGHTNESS = LCD_DEFAULT_BRIGHTNESS;
	Current_Status.LCD_BRIGHTNESS_CHANGED = 1;

	if (Current_Status.LCD_BRIGHTNESS_CHANGED == 1) {
		htim13.Instance->CCR1 = Current_Status.LCD_BRIGHTNESS;
		Current_Status.LCD_BRIGHTNESS_CHANGED = 0;
	}
	/* Infinite loop */
	for (;;) {
		osDelay(1);
	}
  /* USER CODE END 5 */
}

__weak void TouchGFX_Task(void *argument)
{
	for (;;) {
		osDelay(1);
	}
}

void Start_LED_Task(void *argument)
{
  /* USER CODE BEGIN Start_LED_Task */
	/* Infinite loop */
	for (;;) {
		HAL_GPIO_TogglePin(LED_ACTIVE_GPIO_Port, LED_ACTIVE_Pin);
		osDelay(100);
		HAL_GPIO_TogglePin(LED_ALERT_GPIO_Port, LED_ALERT_Pin);
		osDelay(100);
//		HAL_GPIO_TogglePin(CAN1_S0_GPIO_Port, CAN1_S0_Pin);
//		osDelay(100);
//		HAL_GPIO_TogglePin(CAN2_S0_GPIO_Port, CAN2_S0_Pin);
//		osDelay(100);

	}
  /* USER CODE END Start_LED_Task */
}

void Start_CAN_Task(void *argument)
{
  /* USER CODE BEGIN Start_CAN_Task */
	/* Infinite loop */
	Current_Status.CAN_PROTOCOL = CAN_AIM;
	Current_Status.PRES_UNIT = kPa;
	Current_Status.TEMP_UNIT = C;
	Current_Status.SPEED_UNIT = Kmh;
	//HAL_GPIO_WritePin(CAN1_S0_GPIO_Port, CAN1_S0_Pin, SET);
	//HAL_GPIO_WritePin(CAN2_S0_GPIO_Port, CAN2_S0_Pin, SET);

	//HAL_GPIO_WritePin(LED_CAN1_GPIO_Port, LED_CAN1_Pin, SET);

	for (;;) {
		if (CAN_ENABLED) {

			if (HAL_CAN_GetRxMessage(&hcan1, CAN_RX_FIFO0, &RxHeader, RxData)
					== HAL_OK) {
				switch (Current_Status.CAN_PROTOCOL) {
				case CAN_LINK:
					switch (RxHeader.StdId) {
					case 0x7E8:
						switch (RxData[2]) {
						case 0x05: //PID-0x05 Engine coolant temperature , range is -40 to 215 deg C , formula == A-40
							Current_Status.ECT = RxData[3] - 40;
							break;
						case 0x0B: // PID-0x0B , MAP , range is 0 to 255 kPa , Formula == A
							Current_Status.MAP = RxData[3];
							break;
						case 0x0C: // PID-0x0C , RPM  , range is 0 to 16383.75 rpm , Formula == 256A+B / 4
							Current_Status.RPM = (uint16_t) ((RxData[4] << 8)
									+ (RxData[3] & 0x00ff));
							break;
						case 0x0D: //PID-0x0D , Vehicle speed , range is 0 to 255 km/h , formula == A
							Current_Status.LF_SPEED = RxData[3];
							break;
						case 0x0E: //PID-0x0E , Ignition Timing advance, range is -64 to 63.5 BTDC , formula == A/2 - 64
							Current_Status.IGN_TIM = RxData[3] / 2 - 64;
							break;
						case 0x0F: //PID-0x0F , Inlet air temperature , range is -40 to 215 deg C, formula == A-40
							Current_Status.IAT = RxData[3] - 40;
							break;
						case 0x11: // PID-0x11 , TPS percentage, range is 0 to 100 percent, formula == 100/256 A
							Current_Status.TPS = 100 / 256 * RxData[3];
							break;
						case 0x13: //PID-0x13 , oxygen sensors present, A0-A3 == bank1 , A4-A7 == bank2
							break;
						case 0x1C: // PID-0x1C obd standard
							break;
						case 0x20: // PID-0x20 PIDs supported [21-40]
							break;
						case 0x22: // PID-0x22 Fuel /Pressure (Relative to manifold vacuum) , range is 0 to 5177.265 kPa , formula == 0.079(256A+B)
							Current_Status.FUELP = 0.079
									* (256 * (uint16_t) (RxData[4] << 8)
											+ (RxData[3] & 0x00ff));
							break;
						case 0x24: // PID-0x24 O2 sensor2, AB: fuel/air equivalence ratio, CD: voltage ,  Formula == (2/65536)(256A +B) , 8/65536(256C+D) , Range is 0 to <2 and 0 to >8V
							Current_Status.LAMBDA1 = (2 / 65536)
									* (256 * (uint16_t) (RxData[4] << 8)
											+ (RxData[3] & 0x00ff)); // , 8 / 65536 * (256 * (uint16_t)(RxData[5] << 8) + (RxData[6] & 0x00ff));
							break;
						case 0x25: // PID-0x25 O2 sensor2, AB fuel/air equivalence ratio, CD voltage ,  2/65536(256A +B) ,8/65536(256C+D) , range is 0 to <2 and 0 to >8V
							Current_Status.LAMBDA2 = (2 / 65536)
									* (256 * (uint16_t) (RxData[4] << 8)
											+ (RxData[3] & 0x00ff)); // , 8 / 65536 * (256 * (uint16_t)(RxData[5] << 8) + (RxData[6] & 0x00ff));
							break;
						case 0x33: // PID-0x33 Absolute Barometric pressure , range is 0 to 255 kPa , formula == A
							Current_Status.BARO = RxData[3];
							break;
						case 0x40: // PIDs supported [41-60]
							break;
						case 0x42: // PID-0x42 control module voltage, 256A+B / 1000 , range is 0 to 65.535v
							Current_Status.BATT = 256
									* (uint16_t) (RxData[4] << 8)
									+ (RxData[3] & 0x00ff) / 1000;
							break;
						case 0x46: // PID-0x46 Ambient Air Temperature , range is -40 to 215 deg C , formula == A-40
							break;
						case 0x52: // PID-0x52 Ethanol fuel % , range is 0 to 100% , formula == (100/255)A
							Current_Status.ETHANOL = 100 / 255 * RxData[3];
							break;
						case 0x5C: // PID-0x5C Engine oil temperature , range is -40 to 210 deg C , formula == A-40
							Current_Status.OILT = RxData[3] - 40;
							break;
						case 0x60: // PIDs supported [61-80]
							break;
						default:
							break;
						}
						break;
					case 0x3E8: //Link Dash
						switch (RxData[0]) {
						case 0:
							Current_Status.RPM = (uint16_t) ((RxData[3] << 8)
									+ (RxData[2] & 0x00ff));
							Current_Status.MAP = (uint16_t) ((RxData[5] << 8)
									+ (RxData[4] & 0x00ff));
							Current_Status.MGP = (uint16_t) ((RxData[7] << 8)
									+ (RxData[6] & 0x00ff));
							break;
						case 1:
							Current_Status.BARO = (uint16_t) ((RxData[3] << 8)
									+ (RxData[2] & 0x00ff));
							Current_Status.TPS = (uint16_t) ((RxData[5] << 8)
									+ (RxData[4] & 0x00ff));
							Current_Status.INJ_DC = (uint16_t) ((RxData[7] << 8)
									+ (RxData[6] & 0x00ff));
							break;
						case 2:
							Current_Status.INJ_DC_ST = (uint16_t) ((RxData[3]
									<< 8) + (RxData[2] & 0x00ff));
							Current_Status.INJ_PULSE = (uint16_t) ((RxData[5]
									<< 8) + (RxData[4] & 0x00ff));
							Current_Status.ECT = (uint16_t) ((RxData[7] << 8)
									+ (RxData[6] & 0x00ff));
							break;
						case 3:
							Current_Status.IAT = (uint16_t) ((RxData[3] << 8)
									+ (RxData[2] & 0x00ff));
							Current_Status.BATT = (uint16_t) ((RxData[5] << 8)
									+ (RxData[4] & 0x00ff));
							Current_Status.MAF = (uint16_t) ((RxData[7] << 8)
									+ (RxData[6] & 0x00ff));
							break;
						case 4:
							Current_Status.GEAR = (uint16_t) ((RxData[3] << 8)
									+ (RxData[2] & 0x00ff));
							Current_Status.INJ_TIM =
									(uint16_t) ((RxData[5] << 8)
											+ (RxData[4] & 0x00ff));
							Current_Status.IGN_TIM =
									(uint16_t) ((RxData[7] << 8)
											+ (RxData[6] & 0x00ff));
							break;
						case 5:
							Current_Status.CAM_I_L =
									(uint16_t) ((RxData[3] << 8)
											+ (RxData[2] & 0x00ff));
							Current_Status.CAM_I_R =
									(uint16_t) ((RxData[5] << 8)
											+ (RxData[4] & 0x00ff));
							Current_Status.CAM_E_L =
									(uint16_t) ((RxData[7] << 8)
											+ (RxData[6] & 0x00ff));
							break;
						case 6:
							Current_Status.CAM_E_R =
									(uint16_t) ((RxData[3] << 8)
											+ (RxData[2] & 0x00ff));
							Current_Status.LAMBDA1 =
									(uint16_t) ((RxData[5] << 8)
											+ (RxData[4] & 0x00ff));
							Current_Status.LAMBDA2 =
									(uint16_t) ((RxData[7] << 8)
											+ (RxData[6] & 0x00ff));
							break;
						case 7:
							Current_Status.TRIG1_ERROR = (uint16_t) ((RxData[3]
									<< 8) + (RxData[2] & 0x00ff));
							Current_Status.FAULT_CODES = (uint16_t) ((RxData[5]
									<< 8) + (RxData[4] & 0x00ff));
							Current_Status.FUELP = (uint16_t) ((RxData[7] << 8)
									+ (RxData[6] & 0x00ff));
							break;
						case 8:
							Current_Status.OILT = (uint16_t) ((RxData[3] << 8)
									+ (RxData[2] & 0x00ff));
							Current_Status.OILP = (uint16_t) ((RxData[5] << 8)
									+ (RxData[4] & 0x00ff));
							Current_Status.LF_SPEED = (uint16_t) ((RxData[7]
									<< 8) + (RxData[6] & 0x00ff));
							break;
						case 9:
							Current_Status.LR_SPEED = (uint16_t) ((RxData[3]
									<< 8) + (RxData[2] & 0x00ff));
							Current_Status.RF_SPEED = (uint16_t) ((RxData[5]
									<< 8) + (RxData[4] & 0x00ff));
							Current_Status.RR_SPEED = (uint16_t) ((RxData[7]
									<< 8) + (RxData[6] & 0x00ff));
							break;
						case 10:
							Current_Status.KNOCK1 = (uint16_t) ((RxData[3] << 8)
									+ (RxData[2] & 0x00ff));
							Current_Status.KNOCK2 = (uint16_t) ((RxData[5] << 8)
									+ (RxData[4] & 0x00ff));
							Current_Status.KNOCK3 = (uint16_t) ((RxData[7] << 8)
									+ (RxData[6] & 0x00ff));
							break;
						case 11:
							Current_Status.KNOCK4 = (uint16_t) ((RxData[3] << 8)
									+ (RxData[2] & 0x00ff));
							Current_Status.KNOCK5 = (uint16_t) ((RxData[5] << 8)
									+ (RxData[4] & 0x00ff));
							Current_Status.KNOCK6 = (uint16_t) ((RxData[7] << 8)
									+ (RxData[6] & 0x00ff));
							break;
						case 12:
							Current_Status.KNOCK7 = (uint16_t) ((RxData[3] << 8)
									+ (RxData[2] & 0x00ff));
							Current_Status.KNOCK8 = (uint16_t) ((RxData[5] << 8)
									+ (RxData[4] & 0x00ff));
							Current_Status.LIMITS = (uint16_t) ((RxData[7] << 8)
									+ (RxData[6] & 0x00ff));
							break;
						}
						break;
					}
					break;
				case CAN_AIM:
					switch (RxHeader.StdId) {
					case 0x5F0:
						Current_Status.RPM = (uint16_t) ((RxData[1] << 8) + (RxData[0] & 0x00ff));
						Current_Status.TPS = (uint16_t)((RxData[3] << 8) + (RxData[2] & 0x00ff)) / 65;
						break;
					case 0x5F2:
						Current_Status.IAT = (uint16_t)((RxData[1] << 8) + (RxData[0] & 0x00ff)) / 19 - 450;
						Current_Status.ECT = (uint16_t)((RxData[3] << 8) + (RxData[2] & 0x00ff)) / 19 - 450;
						Current_Status.FUELT = (uint16_t)((RxData[5] << 8) + (RxData[4] & 0x00ff)) / 19 - 450;
						Current_Status.OILT = (uint16_t)((RxData[7] << 8) + (RxData[6] & 0x00ff)) / 19 - 450;
						break;
					case 0x5F3:
						Current_Status.MAP = (uint16_t)((RxData[1] << 8) + (RxData[0] & 0x00ff)) / 10;
						Current_Status.BARO = (uint16_t)((RxData[3] << 8) + (RxData[2] & 0x00ff)) / 10;
						Current_Status.OILP = (uint16_t)((RxData[5] << 8) + (RxData[4] & 0x00ff)) * 100 / 100;
						Current_Status.FUELP = (uint16_t)((RxData[7] << 8) + (RxData[6] & 0x00ff)) * 100 / 2;
						break;
					case 0x5F4:
						Current_Status.BATT = (uint16_t)((RxData[3] << 8) + (RxData[2] & 0x00ff)) / 32;
						//Current_Status.GEAR = (uint16_t)((RxData[7] << 8) + (RxData[6] & 0x00ff));
						break;
					case 0x5F6:
						Current_Status.LAMBDA1 = (uint16_t)((RxData[1] << 8) + (RxData[0] & 0x00ff)) / 2;
						Current_Status.LAMBDA2 = (uint16_t)((RxData[3] << 8) + (RxData[2] & 0x00ff)) / 2;
						break;
					}
					break;
				default:
					break;
				}

				if(RxHeader.StdId == CAN_SETUP_ID)
				{
					switch (RxData[0]) {
						case 0x00: //READ START

							break;
						case 0xA0: //SETUP DEVICE

							break;
						case 0xB0: //SETUP FIELD
							//setAllFields(&RxData);
							break;
						case 0xC0: //SETUP CHANNEL

							break;
						case 0xD0: //SETUP ERROR

							break;
					}
				}

				Current_Status.RPM_100 = mapInt(Current_Status.RPM, 0,
						PROTECTION_RPM_HIGH, 0, 100);
				Current_Status.RPM_100 =
						Current_Status.RPM_100 >= 100 ?
								100 : Current_Status.RPM_100;
				Current_Status.RPM_180 = mapInt(Current_Status.RPM, 0,
						PROTECTION_RPM_HIGH, 0, 180);
				Current_Status.RPM_180 =
						Current_Status.RPM_180 >= 180 ?
								810 : Current_Status.RPM_180;
				Current_Status.RPM_270 = mapInt(Current_Status.RPM, 0,
						PROTECTION_RPM_HIGH, 0, 270);
				Current_Status.RPM_270 =
						Current_Status.RPM_270 >= 270 ?
								270 : Current_Status.RPM_270;
				Current_Status.RPM_240 = mapInt(Current_Status.RPM, 0,
						PROTECTION_RPM_HIGH, 0, 240);
				Current_Status.RPM_240 =
						Current_Status.RPM_240 >= 240 ?
								240 : Current_Status.RPM_240;
				Current_Status.RPM_360 = mapInt(Current_Status.RPM, 0,
						PROTECTION_RPM_HIGH, 0, 360);
				Current_Status.RPM_360 =
						Current_Status.RPM_360 >= 360 ?
								360 : Current_Status.RPM_360;

			}
			else {

			}
		} else {
			osDelay(60000);
		}
	}
  /* USER CODE END Start_CAN_Task */
}

void Start_ALERT_Task(void *argument)
{
  /* USER CODE BEGIN Start_ALERT_Task */
	strcpy(Current_Status.SCREEN_FIELDS[0].Label.Label, "Coolant Temperature");
	Current_Status.SCREEN_FIELDS[0].Label.X = 23;
	Current_Status.SCREEN_FIELDS[0].Label.Y = 81;
	Current_Status.SCREEN_FIELDS[0].Label.Width = 101;
	Current_Status.SCREEN_FIELDS[0].Label.Height = 30;
	Current_Status.SCREEN_FIELDS[0].Label.Alignment = LEFT;

	strcpy(Current_Status.SCREEN_FIELDS[0].Unit.Label, "°C");
	Current_Status.SCREEN_FIELDS[0].Unit.X = 390;
	Current_Status.SCREEN_FIELDS[0].Unit.Y = 81;
	Current_Status.SCREEN_FIELDS[0].Unit.Width = 101;
	Current_Status.SCREEN_FIELDS[0].Unit.Height = 30;
	Current_Status.SCREEN_FIELDS[0].Unit.Alignment = LEFT;

	strcpy(Current_Status.SCREEN_FIELDS[0].ValueDefault, "0");
	Current_Status.SCREEN_FIELDS[0].Value.X = 23;
	Current_Status.SCREEN_FIELDS[0].Value.Y = 4;
	Current_Status.SCREEN_FIELDS[0].Value.Width = 44;
	Current_Status.SCREEN_FIELDS[0].Value.Height = 96;
	Current_Status.SCREEN_FIELDS[0].Value.Alignment = LEFT;

	strcpy(Current_Status.SCREEN_FIELDS[1].Label.Label, "Intake Air Temperature");
	Current_Status.SCREEN_FIELDS[1].Label.X = 23;
	Current_Status.SCREEN_FIELDS[1].Label.Y = 196;
	Current_Status.SCREEN_FIELDS[1].Label.Width = 101;
	Current_Status.SCREEN_FIELDS[1].Label.Height = 30;
	Current_Status.SCREEN_FIELDS[1].Label.Alignment = LEFT;

	strcpy(Current_Status.SCREEN_FIELDS[1].Unit.Label, "°C");
	Current_Status.SCREEN_FIELDS[1].Unit.X = 355;
	Current_Status.SCREEN_FIELDS[1].Unit.Y = 196;
	Current_Status.SCREEN_FIELDS[1].Unit.Width = 101;
	Current_Status.SCREEN_FIELDS[1].Unit.Height = 30;
	Current_Status.SCREEN_FIELDS[1].Unit.Alignment = LEFT;

	strcpy(Current_Status.SCREEN_FIELDS[1].ValueDefault, "0");
	Current_Status.SCREEN_FIELDS[1].Value.X = 23;
	Current_Status.SCREEN_FIELDS[1].Value.Y = 119;
	Current_Status.SCREEN_FIELDS[1].Value.Width = 44;
	Current_Status.SCREEN_FIELDS[1].Value.Height = 96;
	Current_Status.SCREEN_FIELDS[1].Value.Alignment = LEFT;

	strcpy(Current_Status.SCREEN_FIELDS[2].Label.Label, "OIL Pressure");
	Current_Status.SCREEN_FIELDS[2].Label.X = 23;
	Current_Status.SCREEN_FIELDS[2].Label.Y = 315;
	Current_Status.SCREEN_FIELDS[2].Label.Width = 101;
	Current_Status.SCREEN_FIELDS[2].Label.Height = 30;
	Current_Status.SCREEN_FIELDS[2].Label.Alignment = LEFT;

	strcpy(Current_Status.SCREEN_FIELDS[2].Unit.Label, "kPa");
	Current_Status.SCREEN_FIELDS[2].Unit.X = 360;
	Current_Status.SCREEN_FIELDS[2].Unit.Y = 315;
	Current_Status.SCREEN_FIELDS[2].Unit.Width = 101;
	Current_Status.SCREEN_FIELDS[2].Unit.Height = 30;
	Current_Status.SCREEN_FIELDS[2].Unit.Alignment = LEFT;

	strcpy(Current_Status.SCREEN_FIELDS[2].ValueDefault, "0");
	Current_Status.SCREEN_FIELDS[2].Value.X = 23;
	Current_Status.SCREEN_FIELDS[2].Value.Y = 238;
	Current_Status.SCREEN_FIELDS[2].Value.Width = 44;
	Current_Status.SCREEN_FIELDS[2].Value.Height = 96;
	Current_Status.SCREEN_FIELDS[2].Value.Alignment = LEFT;

	strcpy(Current_Status.SCREEN_FIELDS[3].Label.Label, "FUEL Pressure");
	Current_Status.SCREEN_FIELDS[3].Label.X = 23;
	Current_Status.SCREEN_FIELDS[3].Label.Y = 430;
	Current_Status.SCREEN_FIELDS[3].Label.Width = 101;
	Current_Status.SCREEN_FIELDS[3].Label.Height = 30;
	Current_Status.SCREEN_FIELDS[3].Label.Alignment = LEFT;

	strcpy(Current_Status.SCREEN_FIELDS[3].Unit.Label, "°C");
	Current_Status.SCREEN_FIELDS[3].Unit.X = 450;
	Current_Status.SCREEN_FIELDS[3].Unit.Y = 430;
	Current_Status.SCREEN_FIELDS[3].Unit.Width = 101;
	Current_Status.SCREEN_FIELDS[3].Unit.Height = 30;
	Current_Status.SCREEN_FIELDS[3].Unit.Alignment = LEFT;

	strcpy(Current_Status.SCREEN_FIELDS[3].ValueDefault, "0");
	Current_Status.SCREEN_FIELDS[3].Value.X = 23;
	Current_Status.SCREEN_FIELDS[3].Value.Y = 353;
	Current_Status.SCREEN_FIELDS[3].Value.Width = 44;
	Current_Status.SCREEN_FIELDS[3].Value.Height = 96;
	Current_Status.SCREEN_FIELDS[3].Value.Alignment = LEFT;

	strcpy(Current_Status.SCREEN_FIELDS[4].Label.Label, "Manifold Pressure");
	Current_Status.SCREEN_FIELDS[4].Label.X = 1160;
	Current_Status.SCREEN_FIELDS[4].Label.Y = 81;
	Current_Status.SCREEN_FIELDS[4].Label.Width = 101;
	Current_Status.SCREEN_FIELDS[4].Label.Height = 30;
	Current_Status.SCREEN_FIELDS[4].Label.Alignment = LEFT;

	strcpy(Current_Status.SCREEN_FIELDS[4].Unit.Label, "°C");
	Current_Status.SCREEN_FIELDS[4].Unit.X = 825;
	Current_Status.SCREEN_FIELDS[4].Unit.Y = 81;
	Current_Status.SCREEN_FIELDS[4].Unit.Width = 101;
	Current_Status.SCREEN_FIELDS[4].Unit.Height = 30;
	Current_Status.SCREEN_FIELDS[4].Unit.Alignment = LEFT;

	strcpy(Current_Status.SCREEN_FIELDS[4].ValueDefault, "0");
	Current_Status.SCREEN_FIELDS[4].Value.X = 1220;
	Current_Status.SCREEN_FIELDS[4].Value.Y = 4;
	Current_Status.SCREEN_FIELDS[4].Value.Width = 44;
	Current_Status.SCREEN_FIELDS[4].Value.Height = 96;
	Current_Status.SCREEN_FIELDS[4].Value.Alignment = LEFT;

	strcpy(Current_Status.SCREEN_FIELDS[5].Label.Label, "Battery");
	Current_Status.SCREEN_FIELDS[5].Label.X = 1160;
	Current_Status.SCREEN_FIELDS[5].Label.Y = 196;
	Current_Status.SCREEN_FIELDS[5].Label.Width = 101;
	Current_Status.SCREEN_FIELDS[5].Label.Height = 30;
	Current_Status.SCREEN_FIELDS[5].Label.Alignment = LEFT;

	strcpy(Current_Status.SCREEN_FIELDS[5].Unit.Label, "°C");
	Current_Status.SCREEN_FIELDS[5].Unit.X = 868;
	Current_Status.SCREEN_FIELDS[5].Unit.Y = 196;
	Current_Status.SCREEN_FIELDS[5].Unit.Width = 101;
	Current_Status.SCREEN_FIELDS[5].Unit.Height = 30;
	Current_Status.SCREEN_FIELDS[5].Unit.Alignment = LEFT;

	strcpy(Current_Status.SCREEN_FIELDS[5].ValueDefault, "0");
	Current_Status.SCREEN_FIELDS[5].Value.X = 1220;
	Current_Status.SCREEN_FIELDS[5].Value.Y = 119;
	Current_Status.SCREEN_FIELDS[5].Value.Width = 44;
	Current_Status.SCREEN_FIELDS[5].Value.Height = 96;
	Current_Status.SCREEN_FIELDS[5].Value.Alignment = LEFT;

	strcpy(Current_Status.SCREEN_FIELDS[6].Label.Label, "Throttle Position");
	Current_Status.SCREEN_FIELDS[6].Label.X = 1160;
	Current_Status.SCREEN_FIELDS[6].Label.Y = 315;
	Current_Status.SCREEN_FIELDS[6].Label.Width = 101;
	Current_Status.SCREEN_FIELDS[6].Label.Height = 30;
	Current_Status.SCREEN_FIELDS[6].Label.Alignment = LEFT;

	strcpy(Current_Status.SCREEN_FIELDS[6].Unit.Label, "kPa");
	Current_Status.SCREEN_FIELDS[6].Unit.X = 858;
	Current_Status.SCREEN_FIELDS[6].Unit.Y = 315;
	Current_Status.SCREEN_FIELDS[6].Unit.Width = 101;
	Current_Status.SCREEN_FIELDS[6].Unit.Height = 30;
	Current_Status.SCREEN_FIELDS[6].Unit.Alignment = LEFT;

	strcpy(Current_Status.SCREEN_FIELDS[6].ValueDefault, "0");
	Current_Status.SCREEN_FIELDS[6].Value.X = 1220;
	Current_Status.SCREEN_FIELDS[6].Value.Y = 238;
	Current_Status.SCREEN_FIELDS[6].Value.Width = 44;
	Current_Status.SCREEN_FIELDS[6].Value.Height = 96;
	Current_Status.SCREEN_FIELDS[6].Value.Alignment = LEFT;

	strcpy(Current_Status.SCREEN_FIELDS[7].Label.Label, "Wideband");
	Current_Status.SCREEN_FIELDS[7].Label.X = 1160;
	Current_Status.SCREEN_FIELDS[7].Label.Y = 430;
	Current_Status.SCREEN_FIELDS[7].Label.Width = 101;
	Current_Status.SCREEN_FIELDS[7].Label.Height = 30;
	Current_Status.SCREEN_FIELDS[7].Label.Alignment = LEFT;

	strcpy(Current_Status.SCREEN_FIELDS[7].Unit.Label, "°C");
	Current_Status.SCREEN_FIELDS[7].Unit.X = 770;
	Current_Status.SCREEN_FIELDS[7].Unit.Y = 430;
	Current_Status.SCREEN_FIELDS[7].Unit.Width = 101;
	Current_Status.SCREEN_FIELDS[7].Unit.Height = 30;
	Current_Status.SCREEN_FIELDS[7].Unit.Alignment = LEFT;

	strcpy(Current_Status.SCREEN_FIELDS[7].ValueDefault, "0");
	Current_Status.SCREEN_FIELDS[7].Value.X = 1220;
	Current_Status.SCREEN_FIELDS[7].Value.Y = 353;
	Current_Status.SCREEN_FIELDS[7].Value.Width = 44;
	Current_Status.SCREEN_FIELDS[7].Value.Height = 96;
	Current_Status.SCREEN_FIELDS[7].Value.Alignment = LEFT;

//	Current_Status.SCREEN_FIELDS[1].Label.Label = "IAT";
//	Current_Status.SCREEN_FIELDS[1].Unit.Label = "°C";
//
//	Current_Status.SCREEN_FIELDS[2].Label.Label = "Oil Pressure";
//	Current_Status.SCREEN_FIELDS[2].Unit.Label = "kPa";
//
//	Current_Status.SCREEN_FIELDS[3].Label.Label = "Fuel Pressure";
//	Current_Status.SCREEN_FIELDS[3].Unit.Label = "kPa";
//
//	Current_Status.SCREEN_FIELDS[4].Label.Label = "MAP";
//	Current_Status.SCREEN_FIELDS[4].Unit.Label = "kPa";
//
//	Current_Status.SCREEN_FIELDS[5].Label.Label = "Battery";
//	Current_Status.SCREEN_FIELDS[5].Unit.Label = "V";
//
//	Current_Status.SCREEN_FIELDS[6].Label.Label = "TPS";
//	Current_Status.SCREEN_FIELDS[6].Unit.Label = "%";
//
//	Current_Status.SCREEN_FIELDS[7].Label.Label = "Wideband";
//	Current_Status.SCREEN_FIELDS[7].Unit.Label = "Lambda";

	TickType_t xStart, xEnd, xDifference;

  /* Infinite loop */
  for(;;)
  {
//		Current_Status.OK_L1 = true;
//		Current_Status.ALERT_L1 = false;
//		Current_Status.WARNING_L1 = false;
//		osDelay(100);
//		Current_Status.OK_L1 = false;
//		Current_Status.ALERT_L1 = false;
//		Current_Status.WARNING_L1 = true;
//		osDelay(100);
//		Current_Status.OK_L1 = false;
//		Current_Status.ALERT_L1 = true;
//		Current_Status.WARNING_L1 = false;
//		osDelay(100);
//		Current_Status.OK_L1 = false;
//		Current_Status.ALERT_L1 = false;
//		Current_Status.WARNING_L1 = false;
//		osDelay(100);
//
//		Current_Status.OK_L2 = true;
//		Current_Status.ALERT_L2 = false;
//		Current_Status.WARNING_L2 = false;
//		osDelay(100);
//		Current_Status.OK_L2 = false;
//		Current_Status.ALERT_L2 = false;
//		Current_Status.WARNING_L2 = true;
//		osDelay(100);
//		Current_Status.OK_L2 = false;
//		Current_Status.ALERT_L2 = true;
//		Current_Status.WARNING_L2 = false;
//		osDelay(100);
//		Current_Status.OK_L2 = false;
//		Current_Status.ALERT_L2 = false;
//		Current_Status.WARNING_L2 = false;
//		osDelay(100);
//
//		Current_Status.OK_L3 = true;
//		Current_Status.ALERT_L3 = false;
//		Current_Status.WARNING_L3 = false;
//		osDelay(100);
//		Current_Status.OK_L3 = false;
//		Current_Status.ALERT_L3 = false;
//		Current_Status.WARNING_L3 = true;
//		osDelay(100);
//		Current_Status.OK_L3 = false;
//		Current_Status.ALERT_L3 = true;
//		Current_Status.WARNING_L3 = false;
//		osDelay(100);
//		Current_Status.OK_L3 = false;
//		Current_Status.ALERT_L3 = false;
//		Current_Status.WARNING_L3 = false;
//		osDelay(100);
//
//		Current_Status.OK_L4 = true;
//		Current_Status.ALERT_L4 = false;
//		Current_Status.WARNING_L4 = false;
//		osDelay(100);
//		Current_Status.OK_L4 = false;
//		Current_Status.ALERT_L4 = false;
//		Current_Status.WARNING_L4 = true;
//		osDelay(100);
//		Current_Status.OK_L4 = false;
//		Current_Status.ALERT_L4 = true;
//		Current_Status.WARNING_L4 = false;
//		osDelay(100);
//		Current_Status.OK_L4 = false;
//		Current_Status.ALERT_L4 = false;
//		Current_Status.WARNING_L4 = false;
		osDelay(1);
  }
  /* USER CODE END Start_ALERT_Task */
}

void Start_RGB_Task(void *argument)
{
  /* USER CODE BEGIN Start_RGB_Task */

    setWS2812Brightness(5);
		/* Infinite loop */
		for (;;) {
				if (RGB_ENABLED) {
					//Current_Status.RPM = Current_Status.RPM >= PROTECTION_RPM_HIGH ? 0 : Current_Status.RPM;
					//Current_Status.RPM = Current_Status.RPM + 100;

					Current_Status.ENGINE_PROTECTION = Current_Status.RPM >= PROTECTION_RPM_HIGH ? 1 : 0;

					clearWS2812All();
					uint8_t RPMLED = WS2812_LED_N;

					uint16_t lowRange = mapInt(Current_Status.RPM, PROTECTION_RPM_LOW, 0, RPMLED - PROTECTION_RPM_LED, 1);
					lowRange = lowRange > RPMLED - PROTECTION_RPM_LED ? RPMLED - PROTECTION_RPM_LED : lowRange;
					lowRange = lowRange < 1 ? 1 : lowRange;

					for (int i = 1; i <= lowRange; i++) {
						WS2812_RGB_t color;
						if (Current_Status.ENGINE_PROTECTION == 1) {
							color.red = 0;
							color.green = 255;
							color.blue = 0;
						} else {
							color.red = 0;
							color.green = 255;
							color.blue = 0;
						}
						setWS2812One((RPMLED - i) + (WS2812_LED_N - RPMLED), color);
					}

					if (Current_Status.RPM > PROTECTION_RPM_LOW) {
						uint16_t highRange = mapInt(Current_Status.RPM, PROTECTION_RPM_HIGH, PROTECTION_RPM_LOW, PROTECTION_RPM_LED, 1);
						for (int i = 1; i <= highRange; i++) {
							WS2812_RGB_t color;
							color.red = 255;
							color.green = 0;
							color.blue = 0;

							setWS2812One((PROTECTION_RPM_LED - i) + (WS2812_LED_N - RPMLED), color);
						}

						updateWS2812();
						osDelay(50);

						for (int i = 1; i <= highRange; i++) {
							WS2812_RGB_t color;
							color.red = 0;
							color.green = 0;
							color.blue = 0;

							setWS2812One((PROTECTION_RPM_LED - i) + (WS2812_LED_N - RPMLED), color);
						}
					}

					updateWS2812();
					osDelay(100);
				}
			}
  /* USER CODE END Start_RGB_Task */
}

void HAL_TIM_PeriodElapsedCallback(TIM_HandleTypeDef *htim)
{
  if (htim->Instance == TIM6) {
    HAL_IncTick();
  }
}

void Error_Handler(void)
{
	__disable_irq();
	while (1) {
	}
}
